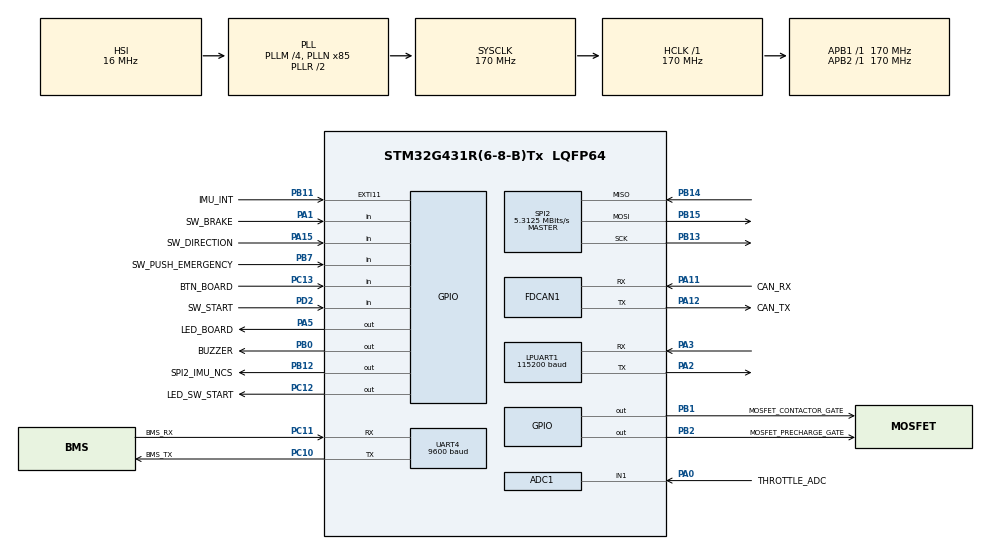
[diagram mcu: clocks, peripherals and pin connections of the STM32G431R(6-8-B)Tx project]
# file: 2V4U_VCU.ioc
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ADC1.Channel-1\#ChannelRegularConversion=ADC_CHANNEL_1
ADC1.ContinuousConvMode=ENABLE
ADC1.DMAContinuousRequests=ENABLE
ADC1.NbrOfConversionFlag=1
ADC1.OffsetNumber-1\#ChannelRegularConversion=ADC_OFFSET_NONE
ADC1.Rank-1\#ChannelRegularConversion=1
ADC1.SamplingTime-1\#ChannelRegularConversion=ADC_SAMPLETIME_47CYCLES_5
ADC1.master=1
Dma.ADC1.0.Direction=DMA_PERIPH_TO_MEMORY
Dma.ADC1.0.EventEnable=DISABLE
Dma.ADC1.0.Instance=DMA1_Channel1
Dma.ADC1.0.MemDataAlignment=DMA_MDATAALIGN_HALFWORD
Dma.ADC1.0.MemInc=DMA_MINC_ENABLE
Dma.ADC1.0.Mode=DMA_CIRCULAR
Dma.ADC1.0.PeriphDataAlignment=DMA_PDATAALIGN_HALFWORD
Dma.ADC1.0.PeriphInc=DMA_PINC_DISABLE
Dma.ADC1.0.Polarity=HAL_DMAMUX_REQ_GEN_RISING
Dma.ADC1.0.Priority=DMA_PRIORITY_LOW
Dma.ADC1.0.RequestNumber=1
Dma.ADC1.0.SignalID=NONE
Dma.ADC1.0.SyncEnable=DISABLE
Dma.ADC1.0.SyncPolarity=HAL_DMAMUX_SYNC_NO_EVENT
Dma.ADC1.0.SyncRequestNumber=1
Dma.ADC1.0.SyncSignalID=NONE
Dma.Request0=ADC1
Dma.Request1=UART4_RX
Dma.UART4_RX.1.Direction=DMA_PERIPH_TO_MEMORY
Dma.UART4_RX.1.EventEnable=DISABLE
Dma.UART4_RX.1.Instance=DMA1_Channel2
Dma.UART4_RX.1.MemDataAlignment=DMA_MDATAALIGN_BYTE
Dma.UART4_RX.1.MemInc=DMA_MINC_ENABLE
Dma.UART4_RX.1.Mode=DMA_NORMAL
Dma.UART4_RX.1.PeriphDataAlignment=DMA_PDATAALIGN_BYTE
Dma.UART4_RX.1.PeriphInc=DMA_PINC_DISABLE
Dma.UART4_RX.1.Polarity=HAL_DMAMUX_REQ_GEN_RISING
Dma.UART4_RX.1.Priority=DMA_PRIORITY_LOW
Dma.UART4_RX.1.RequestNumber=1
Dma.UART4_RX.1.SignalID=NONE
Dma.UART4_RX.1.SyncEnable=DISABLE
Dma.UART4_RX.1.SyncPolarity=HAL_DMAMUX_SYNC_NO_EVENT
Dma.UART4_RX.1.SyncRequestNumber=1
Dma.UART4_RX.1.SyncSignalID=NONE
FDCAN1.CalculateBaudRateNominal=499999
FDCAN1.CalculateTimeBitNominal=2000
FDCAN1.CalculateTimeQuantumNominal=117.64705882352942
FDCAN1.NominalPrescaler=20
FDCAN1.NominalTimeSeg1=13
FDCAN1.NominalTimeSeg2=3
IWDG.Prescaler=IWDG_PRESCALER_64
IWDG.Reload=50
LPUART1.BaudRate=115200
Mcu.Family=STM32G4
Mcu.Name=STM32G431R(6-8-B)Tx
Mcu.Package=LQFP64
NUCLEO-G431RB.BUTTON=0
NUCLEO-G431RB.LD1=false
NUCLEO-G431RB.VCP=false
NVIC.DMA1_Channel1_IRQn=true\:0\:0\:false\:false\:true\:false\:true\:true
NVIC.DMA1_Channel2_IRQn=true\:0\:0\:false\:false\:true\:false\:true\:true
NVIC.EXTI15_10_IRQn=true\:3\:0\:true\:false\:true\:true\:true\:true
NVIC.FDCAN1_IT0_IRQn=true\:0\:0\:false\:false\:true\:true\:true\:true
NVIC.PriorityGroup=NVIC_PRIORITYGROUP_4
NVIC.TIM6_DAC_IRQn=true\:0\:0\:false\:false\:true\:true\:true\:true
NVIC.UART4_IRQn=true\:0\:0\:false\:false\:true\:true\:true\:true
PA0.GPIO_Label=THROTTLE_ADC
PA0.Mode=IN1-Single-Ended
PA0.Signal=ADC1_IN1
PA1.GPIO_Label=SW_BRAKE
PA1.GPIO_PuPd=GPIO_PULLUP
PA1.Signal=GPIO_Input
PA11.GPIO_Label=CAN_RX
PA11.Mode=FDCAN_Activate
PA11.Signal=FDCAN1_RX
PA12.GPIO_Label=CAN_TX
PA12.Mode=FDCAN_Activate
PA12.Signal=FDCAN1_TX
PA13.GPIO_Label=T_SWDIO
PA13.Signal=SYS_JTMS-SWDIO
PA14.GPIO_Label=T_SWCLK
PA14.Signal=SYS_JTCK-SWCLK
PA15.GPIO_Label=SW_DIRECTION
PA15.GPIO_PuPd=GPIO_PULLUP
PA15.Signal=GPIO_Input
PA2.Mode=Asynchronous
PA2.Signal=LPUART1_TX
PA3.Mode=Asynchronous
PA3.Signal=LPUART1_RX
PA5.GPIO_Label=LED_BOARD
PA5.Signal=GPIO_Output
PB0.GPIO_Label=BUZZER
PB0.Signal=GPIO_Output
PB1.GPIO_Label=MOSFET_CONTACTOR_GATE
PB1.Signal=GPIO_Output
PB11.GPIO_Label=IMU_INT
PB11.Signal=GPXTI11
PB12.GPIO_Label=SPI2_IMU_NCS
PB12.GPIO_PuPd=GPIO_PULLUP
PB12.GPIO_Speed=GPIO_SPEED_FREQ_VERY_HIGH
PB12.PinState=GPIO_PIN_SET
PB12.Signal=GPIO_Output
PB13.Mode=Full_Duplex_Master
PB13.Signal=SPI2_SCK
PB14.Mode=Full_Duplex_Master
PB14.Signal=SPI2_MISO
PB15.Mode=Full_Duplex_Master
PB15.Signal=SPI2_MOSI
PB2.GPIO_Label=MOSFET_PRECHARGE_GATE
PB2.Signal=GPIO_Output
PB3.GPIO_Label=T_SWO
PB3.Signal=SYS_JTDO-SWO
PB7.GPIO_Label=SW_PUSH_EMERGENCY
PB7.GPIO_PuPd=GPIO_PULLUP
PB7.Signal=GPIO_Input
PC10.GPIO_Label=BMS_TX
PC10.Mode=Asynchronous
PC10.Signal=UART4_TX
PC11.GPIO_Label=BMS_RX
PC11.Mode=Asynchronous
PC11.Signal=UART4_RX
PC12.GPIO_Label=LED_SW_START
PC12.Signal=GPIO_Output
PC13.GPIO_Label=BTN_BOARD
PC13.GPIO_PuPd=GPIO_PULLDOWN
PC13.Signal=GPIO_Input
PC14-OSC32_IN.GPIO_Label=RCC_OSC32_OUT
PC14-OSC32_IN.Signal=RCC_OSC32_IN
PC15-OSC32_OUT.GPIO_Label=RCC_OSC32_OUT
PC15-OSC32_OUT.Signal=RCC_OSC32_OUT
PD2.GPIO_Label=SW_START
PD2.GPIO_PuPd=GPIO_PULLUP
PD2.Signal=GPIO_Input
PF0-OSC_IN.GPIO_Label=RCC_OSC_IN
PF0-OSC_IN.Signal=RCC_OSC_IN
PF1-OSC_OUT.GPIO_Label=RCC_OSC_OUT
PF1-OSC_OUT.Signal=RCC_OSC_OUT
ProjectManager.HeapSize=0x200
ProjectManager.StackSize=0x400
ProjectManager.TargetToolchain=CMake
RCC.ADC12Freq_Value=170000000
RCC.AHBFreq_Value=170000000
RCC.APB1Freq_Value=170000000
RCC.APB1TimFreq_Value=170000000
RCC.APB2Freq_Value=170000000
RCC.APB2TimFreq_Value=170000000
RCC.CortexFreq_Value=170000000
RCC.EXTERNAL_CLOCK_VALUE=12288000
RCC.HCLKFreq_Value=170000000
RCC.HSE_VALUE=24000000
RCC.HSI48_VALUE=48000000
RCC.HSI_VALUE=16000000
RCC.LSE_VALUE=32768
RCC.PLLM=RCC_PLLM_DIV4
RCC.PLLN=85
RCC.RTCClockSelection=RCC_RTCCLKSOURCE_LSE
RCC.SYSCLKFreq_VALUE=170000000
RCC.SYSCLKSource=RCC_SYSCLKSOURCE_PLLCLK
RCC.USBFreq_Value=170000000
RCC.VCOOutputFreq_Value=340000000
SPI2.BaudRatePrescaler=SPI_BAUDRATEPRESCALER_32
SPI2.CLKPhase=SPI_PHASE_2EDGE
SPI2.CLKPolarity=SPI_POLARITY_HIGH
SPI2.CalculateBaudRate=5.3125 MBits/s
SPI2.DataSize=SPI_DATASIZE_8BIT
SPI2.Direction=SPI_DIRECTION_2LINES
SPI2.Mode=SPI_MODE_MASTER
SPI2.VirtualType=VM_MASTER
TIM6.PeriodNoDither=100-1
TIM6.Prescaler=17000-1
UART4.BaudRate=9600
VP_IWDG_VS_IWDG.Mode=IWDG_Activate
VP_NUCLEO-G431RB_VS_BSP_COMMON.Mode=COMMON
VP_SYS_VS_DBSignals.Mode=DisableDeadBatterySignals
VP_TIM6_VS_ClockSourceINT.Mode=Enable_Timer
board=NUCLEO-G431RB

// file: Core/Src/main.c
/* USER CODE BEGIN Header */
/**
  ******************************************************************************
  * @file           : main.c
  * @brief          : Main program body
  ******************************************************************************
  * @attention
  *
  * Copyright (c) 2026 STMicroelectronics.
  * All rights reserved.
  *
  * This software is licensed under terms that can be found in the LICENSE file
  * in the root directory of this software component.
  * If no LICENSE file comes with this software, it is provided AS-IS.
  *
  ******************************************************************************
  */
/* USER CODE END Header */
#include "main.h"
#include "adc.h"
#include "dma.h"
#include "fdcan.h"
#include "iwdg.h"
#include "usart.h"
#include "spi.h"
#include "tim.h"
#include "gpio.h"

/* USER CODE BEGIN Includes */
#include "App.h"
#include <stdio.h>
/* USER CODE END Includes */

/* USER CODE BEGIN PM */
#define ADC_BUFFER_SIZE 100
/* USER CODE END PM */

/* USER CODE BEGIN PV */
extern UART_HandleTypeDef hlpuart1;
volatile uint16_t adcBuffer[ADC_BUFFER_SIZE];
/* USER CODE END PV */

void SystemClock_Config(void);

/* USER CODE BEGIN 0 */
// Printf redirected to this
int _write(int file, char *ptr, int len) {
    HAL_UART_Transmit(&hlpuart1, (uint8_t *)ptr, len, HAL_MAX_DELAY);
    return len;
}
/* USER CODE END 0 */

int main(void)
{

  /* MCU Configuration--------------------------------------------------------*/

  /* Reset of all peripherals, Initializes the Flash interface and the Systick. */
  HAL_Init();

  /* Configure the system clock */
  SystemClock_Config();

  /* Initialize all configured peripherals */
  MX_GPIO_Init();
  MX_DMA_Init();
  MX_FDCAN1_Init();
  MX_ADC1_Init();
  MX_LPUART1_UART_Init();
  MX_SPI2_Init();
  MX_TIM6_Init();
  MX_IWDG_Init();
  MX_UART4_Init();
  /* USER CODE BEGIN 2 */
  HAL_TIM_Base_Start_IT(&htim6);
  HAL_ADCEx_Calibration_Start(&hadc1, ADC_SINGLE_ENDED);
  HAL_ADC_Start_DMA(&hadc1, (uint32_t*)adcBuffer, ADC_BUFFER_SIZE);

  App_Init(adcBuffer);
  setvbuf(stdout, NULL, _IONBF, 0);
  /* USER CODE END 2 */

  /* Infinite loop */
  /* USER CODE BEGIN WHILE */
  while (1)
  {
    App_Run();
    /* USER CODE END WHILE */

  }
}

void SystemClock_Config(void)
{
  RCC_OscInitTypeDef RCC_OscInitStruct = {0};
  RCC_ClkInitTypeDef RCC_ClkInitStruct = {0};

  /** Configure the main internal regulator output voltage
  */
  HAL_PWREx_ControlVoltageScaling(PWR_REGULATOR_VOLTAGE_SCALE1_BOOST);

  /** Initializes the RCC Oscillators according to the specified parameters
  * in the RCC_OscInitTypeDef structure.
  */
  RCC_OscInitStruct.OscillatorType = RCC_OSCILLATORTYPE_HSI|RCC_OSCILLATORTYPE_LSI;
  RCC_OscInitStruct.HSIState = RCC_HSI_ON;
  RCC_OscInitStruct.HSICalibrationValue = RCC_HSICALIBRATION_DEFAULT;
  RCC_OscInitStruct.LSIState = RCC_LSI_ON;
  RCC_OscInitStruct.PLL.PLLState = RCC_PLL_ON;
  RCC_OscInitStruct.PLL.PLLSource = RCC_PLLSOURCE_HSI;
  RCC_OscInitStruct.PLL.PLLM = RCC_PLLM_DIV4;
  RCC_OscInitStruct.PLL.PLLN = 85;
  RCC_OscInitStruct.PLL.PLLP = RCC_PLLP_DIV2;
  RCC_OscInitStruct.PLL.PLLQ = RCC_PLLQ_DIV2;
  RCC_OscInitStruct.PLL.PLLR = RCC_PLLR_DIV2;
  if (HAL_RCC_OscConfig(&RCC_OscInitStruct) != HAL_OK)
  {
    Error_Handler();
  }

  /** Initializes the CPU, AHB and APB buses clocks
  */
  RCC_ClkInitStruct.ClockType = RCC_CLOCKTYPE_HCLK|RCC_CLOCKTYPE_SYSCLK
                              |RCC_CLOCKTYPE_PCLK1|RCC_CLOCKTYPE_PCLK2;
  RCC_ClkInitStruct.SYSCLKSource = RCC_SYSCLKSOURCE_PLLCLK;
  RCC_ClkInitStruct.AHBCLKDivider = RCC_SYSCLK_DIV1;
  RCC_ClkInitStruct.APB1CLKDivider = RCC_HCLK_DIV1;
  RCC_ClkInitStruct.APB2CLKDivider = RCC_HCLK_DIV1;

  if (HAL_RCC_ClockConfig(&RCC_ClkInitStruct, FLASH_LATENCY_4) != HAL_OK)
  {
    Error_Handler();
  }
}

void Error_Handler(void)
{
  __disable_irq();
  while (1)
  {
  }
}
